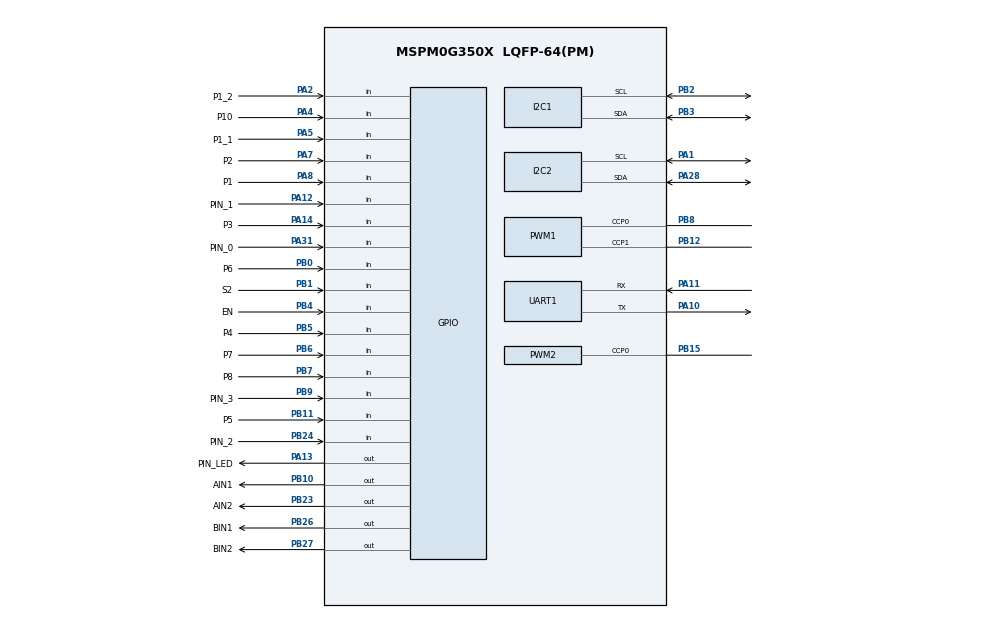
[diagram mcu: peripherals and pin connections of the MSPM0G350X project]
/**
 * @cliArgs --device "MSPM0G350X" --part "Default" --package "LQFP-64(PM)" --product "mspm0_sdk@2.10.00.04"
 * @versions {"tool":"1.26.2+4477"}
 */

/**
 * Import the modules used in this configuration.
 */
const GPIO   = scripting.addModule("/ti/driverlib/GPIO", {}, false);
const GPIO1  = GPIO.addInstance();
const GPIO2  = GPIO.addInstance();
const GPIO3  = GPIO.addInstance();
const GPIO4  = GPIO.addInstance();
const GPIO5  = GPIO.addInstance();
const GPIO6  = GPIO.addInstance();
const I2C    = scripting.addModule("/ti/driverlib/I2C", {}, false);
const I2C1   = I2C.addInstance();
const I2C2   = I2C.addInstance();
const PWM    = scripting.addModule("/ti/driverlib/PWM", {}, false);
const PWM1   = PWM.addInstance();
const PWM2   = PWM.addInstance();
const SYSCTL = scripting.addModule("/ti/driverlib/SYSCTL");
const TIMER  = scripting.addModule("/ti/driverlib/TIMER", {}, false);
const TIMER1 = TIMER.addInstance();
const TIMER2 = TIMER.addInstance();
const TIMER3 = TIMER.addInstance();
const UART   = scripting.addModule("/ti/driverlib/UART", {}, false);
const UART1  = UART.addInstance();

/**
 * Write custom configuration values to the imported modules.
 */
const divider9       = system.clockTree["UDIV"];
divider9.divideValue = 2;

const multiplier2         = system.clockTree["PLL_QDIV"];
multiplier2.multiplyValue = 5;

const mux8       = system.clockTree["HSCLKMUX"];
mux8.inputSelect = "HSCLKMUX_SYSPLL0";

GPIO1.$name                               = "GPIO_EncoderA";
GPIO1.port                                = "PORTA";
GPIO1.associatedPins.create(2);
GPIO1.associatedPins[0].$name             = "PIN_0";
GPIO1.associatedPins[0].direction         = "INPUT";
GPIO1.associatedPins[0].interruptEn       = true;
GPIO1.associatedPins[0].polarity          = "RISE";
GPIO1.associatedPins[0].inputFilter       = "8_CYCLES";
GPIO1.associatedPins[0].interruptPriority = "1";
GPIO1.associatedPins[0].internalResistor  = "PULL_DOWN";
GPIO1.associatedPins[0].pin.$assign       = "PA31";
GPIO1.associatedPins[1].$name             = "PIN_1";
GPIO1.associatedPins[1].direction         = "INPUT";
GPIO1.associatedPins[1].interruptEn       = true;
GPIO1.associatedPins[1].polarity          = "RISE";
GPIO1.associatedPins[1].internalResistor  = "PULL_DOWN";
GPIO1.associatedPins[1].inputFilter       = "8_CYCLES";
GPIO1.associatedPins[1].interruptPriority = "1";
GPIO1.associatedPins[1].pin.$assign       = "PA12";

const Board = scripting.addModule("/ti/driverlib/Board", {}, false);

GPIO2.$name                               = "GPIO_EncoderB";
GPIO2.port                                = "PORTB";
GPIO2.associatedPins.create(2);
GPIO2.associatedPins[0].$name             = "PIN_2";
GPIO2.associatedPins[0].direction         = "INPUT";
GPIO2.associatedPins[0].interruptEn       = true;
GPIO2.associatedPins[0].polarity          = "RISE";
GPIO2.associatedPins[0].inputFilter       = "8_CYCLES";
GPIO2.associatedPins[0].interruptPriority = "1";
GPIO2.associatedPins[0].internalResistor  = "PULL_DOWN";
GPIO2.associatedPins[0].pin.$assign       = "PB24";
GPIO2.associatedPins[1].$name             = "PIN_3";
GPIO2.associatedPins[1].direction         = "INPUT";
GPIO2.associatedPins[1].internalResistor  = "PULL_DOWN";
GPIO2.associatedPins[1].interruptEn       = true;
GPIO2.associatedPins[1].polarity          = "RISE";
GPIO2.associatedPins[1].inputFilter       = "8_CYCLES";
GPIO2.associatedPins[1].interruptPriority = "1";
GPIO2.associatedPins[1].pin.$assign       = "PB9";

GPIO3.$name                              = "DIR";
GPIO3.port                               = "PORTB";
GPIO3.associatedPins.create(4);
GPIO3.associatedPins[0].$name            = "AIN1";
GPIO3.associatedPins[0].internalResistor = "PULL_DOWN";
GPIO3.associatedPins[0].pin.$assign      = "PB10";
GPIO3.associatedPins[1].$name            = "AIN2";
GPIO3.associatedPins[1].pin.$assign      = "PB23";
GPIO3.associatedPins[2].$name            = "BIN1";
GPIO3.associatedPins[2].internalResistor = "PULL_DOWN";
GPIO3.associatedPins[2].pin.$assign      = "PB26";
GPIO3.associatedPins[3].$name            = "BIN2";
GPIO3.associatedPins[3].internalResistor = "PULL_DOWN";
GPIO3.associatedPins[3].pin.$assign      = "PB27";

GPIO4.$name                         = "LED";
GPIO4.associatedPins[0].$name       = "PIN_LED";
GPIO4.associatedPins[0].pin.$assign = "PA13";

GPIO5.$name                          = "Sensor";
GPIO5.associatedPins.create(12);
GPIO5.associatedPins[0].$name        = "P1";
GPIO5.associatedPins[0].direction    = "INPUT";
GPIO5.associatedPins[0].inputFilter  = "1_CYCLE";
GPIO5.associatedPins[0].pin.$assign  = "PA8";
GPIO5.associatedPins[1].direction    = "INPUT";
GPIO5.associatedPins[1].$name        = "P2";
GPIO5.associatedPins[1].inputFilter  = "1_CYCLE";
GPIO5.associatedPins[1].pin.$assign  = "PA7";
GPIO5.associatedPins[2].direction    = "INPUT";
GPIO5.associatedPins[2].$name        = "P3";
GPIO5.associatedPins[2].inputFilter  = "1_CYCLE";
GPIO5.associatedPins[2].pin.$assign  = "PA14";
GPIO5.associatedPins[3].$name        = "P4";
GPIO5.associatedPins[3].direction    = "INPUT";
GPIO5.associatedPins[3].inputFilter  = "1_CYCLE";
GPIO5.associatedPins[3].pin.$assign  = "PB5";
GPIO5.associatedPins[4].$name        = "P5";
GPIO5.associatedPins[4].direction    = "INPUT";
GPIO5.associatedPins[4].inputFilter  = "1_CYCLE";
GPIO5.associatedPins[4].pin.$assign  = "PB11";
GPIO5.associatedPins[5].direction    = "INPUT";
GPIO5.associatedPins[5].$name        = "P6";
GPIO5.associatedPins[5].pin.$assign  = "PB0";
GPIO5.associatedPins[6].$name        = "P7";
GPIO5.associatedPins[6].direction    = "INPUT";
GPIO5.associatedPins[6].pin.$assign  = "PB6";
GPIO5.associatedPins[7].$name        = "P8";
GPIO5.associatedPins[7].direction    = "INPUT";
GPIO5.associatedPins[7].pin.$assign  = "PB7";
GPIO5.associatedPins[8].$name        = "P9";
GPIO5.associatedPins[8].direction    = "INPUT";
GPIO5.associatedPins[9].$name        = "P10";
GPIO5.associatedPins[9].direction    = "INPUT";
GPIO5.associatedPins[9].pin.$assign  = "PA4";
GPIO5.associatedPins[10].$name       = "P1_1";
GPIO5.associatedPins[10].direction   = "INPUT";
GPIO5.associatedPins[10].pin.$assign = "PA5";
GPIO5.associatedPins[11].$name       = "P1_2";
GPIO5.associatedPins[11].direction   = "INPUT";
GPIO5.associatedPins[11].pin.$assign = "PA2";

GPIO6.$name                               = "KEY";
GPIO6.port                                = "PORTB";
GPIO6.associatedPins.create(2);
GPIO6.associatedPins[0].internalResistor  = "PULL_UP";
GPIO6.associatedPins[0].direction         = "INPUT";
GPIO6.associatedPins[0].interruptPriority = "1";
GPIO6.associatedPins[0].inputFilter       = "8_CYCLES";
GPIO6.associatedPins[0].$name             = "S2";
GPIO6.associatedPins[0].pin.$assign       = "PB1";
GPIO6.associatedPins[1].$name             = "EN";
GPIO6.associatedPins[1].direction         = "INPUT";
GPIO6.associatedPins[1].inputFilter       = "8_CYCLES";
GPIO6.associatedPins[1].internalResistor  = "PULL_UP";
GPIO6.associatedPins[1].pin.$assign       = "PB4";

I2C1.$name                             = "I2C_MPU6050";
I2C1.basicEnableController             = true;
I2C1.basicControllerStandardBusSpeed   = "Fast";
I2C1.peripheral.$assign                = "I2C1";
I2C1.peripheral.sdaPin.$assign         = "PB3";
I2C1.peripheral.sclPin.$assign         = "PB2";
I2C1.sdaPinConfig.hideOutputInversion  = scripting.forceWrite(false);
I2C1.sdaPinConfig.onlyInternalResistor = scripting.forceWrite(false);
I2C1.sdaPinConfig.passedPeripheralType = scripting.forceWrite("Digital");
I2C1.sdaPinConfig.$name                = "ti_driverlib_gpio_GPIOPinGeneric2";
I2C1.sclPinConfig.hideOutputInversion  = scripting.forceWrite(false);
I2C1.sclPinConfig.onlyInternalResistor = scripting.forceWrite(false);
I2C1.sclPinConfig.passedPeripheralType = scripting.forceWrite("Digital");
I2C1.sclPinConfig.$name                = "ti_driverlib_gpio_GPIOPinGeneric3";

I2C2.$name                             = "I2C_OLED";
I2C2.basicEnableController             = true;
I2C2.basicControllerStandardBusSpeed   = "Fast";
I2C2.peripheral.$assign                = "I2C0";
I2C2.peripheral.sdaPin.$assign         = "PA28";
I2C2.peripheral.sclPin.$assign         = "PA1";
I2C2.sdaPinConfig.hideOutputInversion  = scripting.forceWrite(false);
I2C2.sdaPinConfig.onlyInternalResistor = scripting.forceWrite(false);
I2C2.sdaPinConfig.passedPeripheralType = scripting.forceWrite("Digital");
I2C2.sdaPinConfig.$name                = "ti_driverlib_gpio_GPIOPinGeneric6";
I2C2.sclPinConfig.hideOutputInversion  = scripting.forceWrite(false);
I2C2.sclPinConfig.onlyInternalResistor = scripting.forceWrite(false);
I2C2.sclPinConfig.passedPeripheralType = scripting.forceWrite("Digital");
I2C2.sclPinConfig.$name                = "ti_driverlib_gpio_GPIOPinGeneric7";

PWM1.$name                          = "PWM_0";
PWM1.timerCount                     = 4000;
PWM1.pwmMode                        = "EDGE_ALIGN_UP";
PWM1.peripheral.$assign             = "TIMA0";
PWM1.peripheral.ccp0Pin.$assign     = "PB8";
PWM1.peripheral.ccp1Pin.$assign     = "PB12";
PWM1.PWM_CHANNEL_0.$name            = "ti_driverlib_pwm_PWMTimerCC0";
PWM1.PWM_CHANNEL_0.dutyCycle        = 50;
PWM1.PWM_CHANNEL_0.shadowUpdateMode = "COMP_UP_EVT";
PWM1.PWM_CHANNEL_1.$name            = "ti_driverlib_pwm_PWMTimerCC1";
PWM1.PWM_CHANNEL_1.dutyCycle        = 50;
PWM1.PWM_CHANNEL_1.shadowUpdateMode = "COMP_UP_EVT";
PWM1.ccp0PinConfig.$name            = "ti_driverlib_gpio_GPIOPinGeneric4";
PWM1.ccp0PinConfig.enableConfig     = true;
PWM1.ccp0PinConfig.internalResistor = "PULL_UP";
PWM1.ccp1PinConfig.$name            = "ti_driverlib_gpio_GPIOPinGeneric5";
PWM1.ccp1PinConfig.enableConfig     = true;
PWM1.ccp1PinConfig.internalResistor = "PULL_UP";

PWM2.$name                              = "SERVO_PWM";
PWM2.ccIndex                            = [0];
PWM2.pwmMode                            = "EDGE_ALIGN_UP";
PWM2.clockPrescale                      = 25;
PWM2.timerCount                         = 10000;
PWM2.PWM_CHANNEL_0.$name                = "ti_driverlib_pwm_PWMTimerCC2";
PWM2.PWM_CHANNEL_0.dutyCycle            = 50;
PWM2.ccp0PinConfig.direction            = scripting.forceWrite("OUTPUT");
PWM2.ccp0PinConfig.hideOutputInversion  = scripting.forceWrite(false);
PWM2.ccp0PinConfig.onlyInternalResistor = scripting.forceWrite(false);
PWM2.ccp0PinConfig.passedPeripheralType = scripting.forceWrite("Digital");
PWM2.ccp0PinConfig.$name                = "ti_driverlib_gpio_GPIOPinGeneric8";
PWM2.peripheral.ccp0Pin.$assign         = "PB15";

SYSCTL.forceDefaultClkConfig = true;
SYSCTL.clockTreeEn           = true;

TIMER1.$name              = "TIMER_0";
TIMER1.timerMode          = "PERIODIC";
TIMER1.interrupts         = ["ZERO"];
TIMER1.timerClkDiv        = 3;
TIMER1.timerPeriod        = "5ms";
TIMER1.timerClkPrescale   = 256;
TIMER1.interruptPriority  = "1";
TIMER1.peripheral.$assign = "TIMA1";

TIMER2.$name              = "TIMER_Encoder_Read";
TIMER2.timerMode          = "PERIODIC";
TIMER2.interrupts         = ["ZERO"];
TIMER2.interruptPriority  = "1";
TIMER2.timerClkPrescale   = 100;
TIMER2.timerClkDiv        = 2;
TIMER2.timerPeriod        = "20ms";
TIMER2.peripheral.$assign = "TIMG6";

TIMER3.$name              = "TIMER_1";
TIMER3.timerClkPrescale   = 256;
TIMER3.timerMode          = "PERIODIC";
TIMER3.interrupts         = ["ZERO"];
TIMER3.interruptPriority  = "0";
TIMER3.timerPeriod        = "1 ms";
TIMER3.peripheral.$assign = "TIMG0";

UART1.$name                        = "UART_0";
UART1.targetBaudRate               = 115200;
UART1.interruptPriority            = "1";
UART1.enabledInterrupts            = ["RX"];
UART1.peripheral.$assign           = "UART0";
UART1.peripheral.rxPin.$assign     = "PA11";
UART1.peripheral.txPin.$assign     = "PA10";
UART1.txPinConfig.$name            = "ti_driverlib_gpio_GPIOPinGeneric0";
UART1.txPinConfig.enableConfig     = true;
UART1.txPinConfig.internalResistor = "PULL_UP";
UART1.rxPinConfig.$name            = "ti_driverlib_gpio_GPIOPinGeneric1";
UART1.rxPinConfig.enableConfig     = true;

/**
 * Pinmux solution for unlocked pins/peripherals. This ensures that minor changes to the automatic solver in a future
 * version of the tool will not impact the pinmux you originally saw.  These lines can be completely deleted in order to
 * re-solve from scratch.
 */
Board.peripheral.$suggestSolution            = "DEBUGSS";
Board.peripheral.swclkPin.$suggestSolution   = "PA20";
Board.peripheral.swdioPin.$suggestSolution   = "PA19";
GPIO5.associatedPins[8].pin.$suggestSolution = "PB13";
PWM2.peripheral.$suggestSolution             = "TIMG7";
